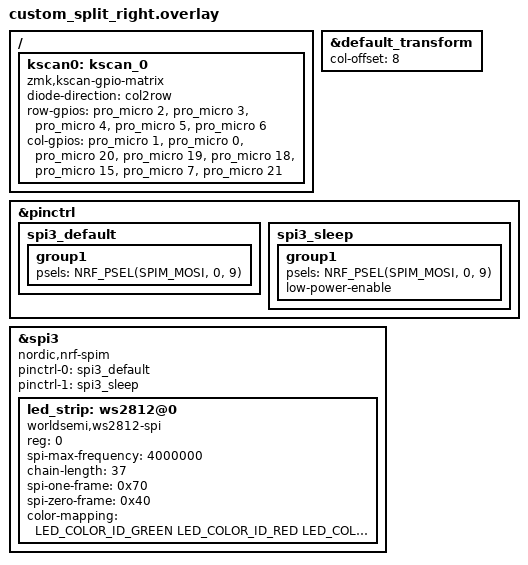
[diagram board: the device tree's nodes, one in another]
#include "custom_split.dtsi"
#include <dt-bindings/led/led.h>
#include <dt-bindings/pinctrl/nrf-pinctrl.h>

&default_transform {
    col-offset = <8>;
};

/ {
    kscan0: kscan_0 {
        compatible = "zmk,kscan-gpio-matrix";
        diode-direction = "col2row";

        // Maps the matching row pins for the right side matrix (physical pins 5,6,7,8,9 / D1,D0,D4,C6,D7)
        row-gpios
            = <&pro_micro 2 (GPIO_ACTIVE_HIGH | GPIO_PULL_DOWN)>
            , <&pro_micro 3 (GPIO_ACTIVE_HIGH | GPIO_PULL_DOWN)>
            , <&pro_micro 4 (GPIO_ACTIVE_HIGH | GPIO_PULL_DOWN)>
            , <&pro_micro 5 (GPIO_ACTIVE_HIGH | GPIO_PULL_DOWN)>
            , <&pro_micro 6 (GPIO_ACTIVE_HIGH | GPIO_PULL_DOWN)>
            ;

        // Maps the right side column pins (mirrored layout, physical pins 1,2,18,19,20,21,10,17)
        col-gpios
            = <&pro_micro 1 GPIO_ACTIVE_HIGH>
            , <&pro_micro 0 GPIO_ACTIVE_HIGH>
            , <&pro_micro 20 GPIO_ACTIVE_HIGH>
            , <&pro_micro 19 GPIO_ACTIVE_HIGH>
            , <&pro_micro 18 GPIO_ACTIVE_HIGH>
            , <&pro_micro 15 GPIO_ACTIVE_HIGH>
            , <&pro_micro 7 GPIO_ACTIVE_HIGH>
            , <&pro_micro 21 GPIO_ACTIVE_HIGH>
            ;
    };
};

// RGB_DATA (physical pin 24 / B6) drives 37 SK6812MINI-E LEDs via a bit-banged SPI bus.
&pinctrl {
    spi3_default: spi3_default {
        group1 {
            psels = <NRF_PSEL(SPIM_MOSI, 0, 9)>;
        };
    };

    spi3_sleep: spi3_sleep {
        group1 {
            psels = <NRF_PSEL(SPIM_MOSI, 0, 9)>;
            low-power-enable;
        };
    };
};

&spi3 {
    compatible = "nordic,nrf-spim";
    status = "okay";

    pinctrl-0 = <&spi3_default>;
    pinctrl-1 = <&spi3_sleep>;
    pinctrl-names = "default", "sleep";

    led_strip: ws2812@0 {
        compatible = "worldsemi,ws2812-spi";

        reg = <0>; /* ignored, but necessary for SPI bindings */
        spi-max-frequency = <4000000>;

        chain-length = <37>;
        spi-one-frame = <0x70>;
        spi-zero-frame = <0x40>;
        color-mapping = <LED_COLOR_ID_GREEN LED_COLOR_ID_RED LED_COLOR_ID_BLUE>;
    };
};
